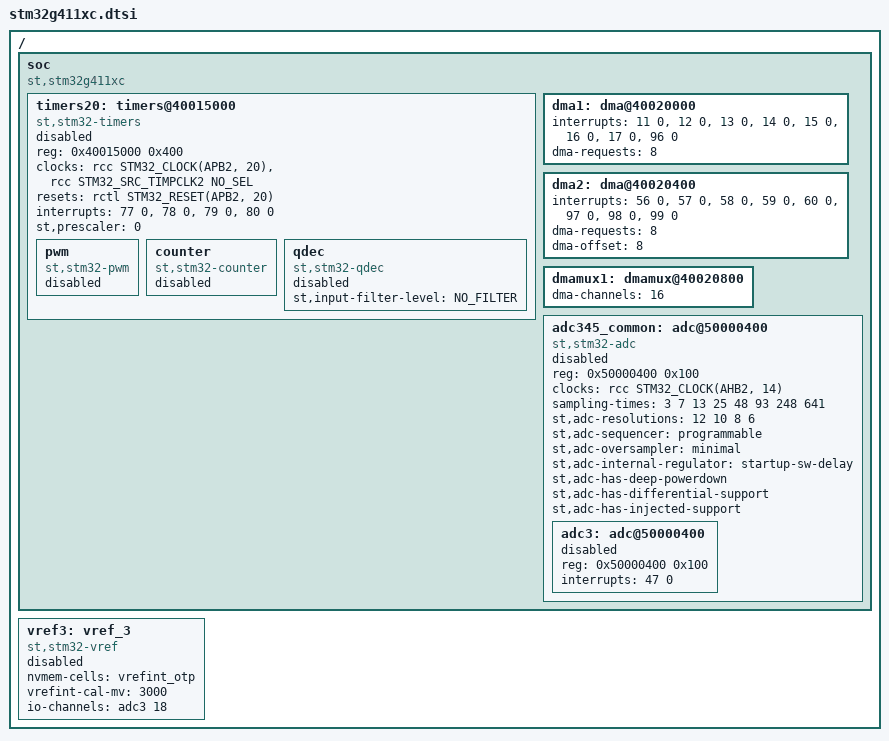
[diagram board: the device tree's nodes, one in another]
/*
 * Copyright (c) 2026 STMicroelectronics
 *
 * SPDX-License-Identifier: Apache-2.0
 */

#include <st/g4/stm32g411xb.dtsi>

/ {
	soc {
		compatible = "st,stm32g411xc", "st,stm32g4", "simple-bus";

		timers20: timers@40015000 {
			compatible = "st,stm32-timers";
			reg = <0x40015000 0x400>;
			clocks = <&rcc STM32_CLOCK(APB2, 20)>,
				 <&rcc STM32_SRC_TIMPCLK2 NO_SEL>;
			resets = <&rctl STM32_RESET(APB2, 20)>;
			interrupts = <77 0>, <78 0>, <79 0>, <80 0>;
			interrupt-names = "brk", "up", "trgcom", "cc";
			st,prescaler = <0>;
			status = "disabled";

			pwm {
				compatible = "st,stm32-pwm";
				#pwm-cells = <3>;
				status = "disabled";
			};

			counter {
				compatible = "st,stm32-counter";
				status = "disabled";
			};

			qdec {
				compatible = "st,stm32-qdec";
				st,input-filter-level = <NO_FILTER>;
				status = "disabled";
			};
		};

		dma1: dma@40020000 {
			interrupts = <11 0>, <12 0>, <13 0>, <14 0>, <15 0>, <16 0>, <17 0>, <96 0>;
			dma-requests = <8>;
		};

		dma2: dma@40020400 {
			interrupts = <56 0>, <57 0>, <58 0>, <59 0>, <60 0>, <97 0>, <98 0>, <99 0>;
			dma-requests = <8>;
			dma-offset = <8>;
		};

		dmamux1: dmamux@40020800 {
			dma-channels = <16>;
		};

		adc345_common: adc@50000400 {
			compatible = "st,stm32-adc";
			reg = <0x50000400 0x100>;
			ranges;
			#address-cells = <1>;
			#size-cells = <1>;
			clocks = <&rcc STM32_CLOCK(AHB2, 14)>;
			clock-names = "adcx";
			sampling-times = <3 7 13 25 48 93 248 641>;
			st,adc-resolutions = <12 10 8 6>;
			st,adc-sequencer = "programmable";
			st,adc-oversampler = "minimal";
			st,adc-internal-regulator = "startup-sw-delay";
			st,adc-has-deep-powerdown;
			st,adc-has-differential-support;
			st,adc-has-injected-support;
			status = "disabled";

			adc3: adc@50000400 {
				reg = <0x50000400 0x100>;
				interrupts = <47 0>;
				#io-channel-cells = <1>;
				status = "disabled";
			};
		};
	};

	vref3: vref_3 {
		compatible = "st,stm32-vref";
		nvmem-cells = <&vrefint_otp>;
		vrefint-cal-mv = <3000>;
		io-channels = <&adc3 18>;
		status = "disabled";
	};
};
